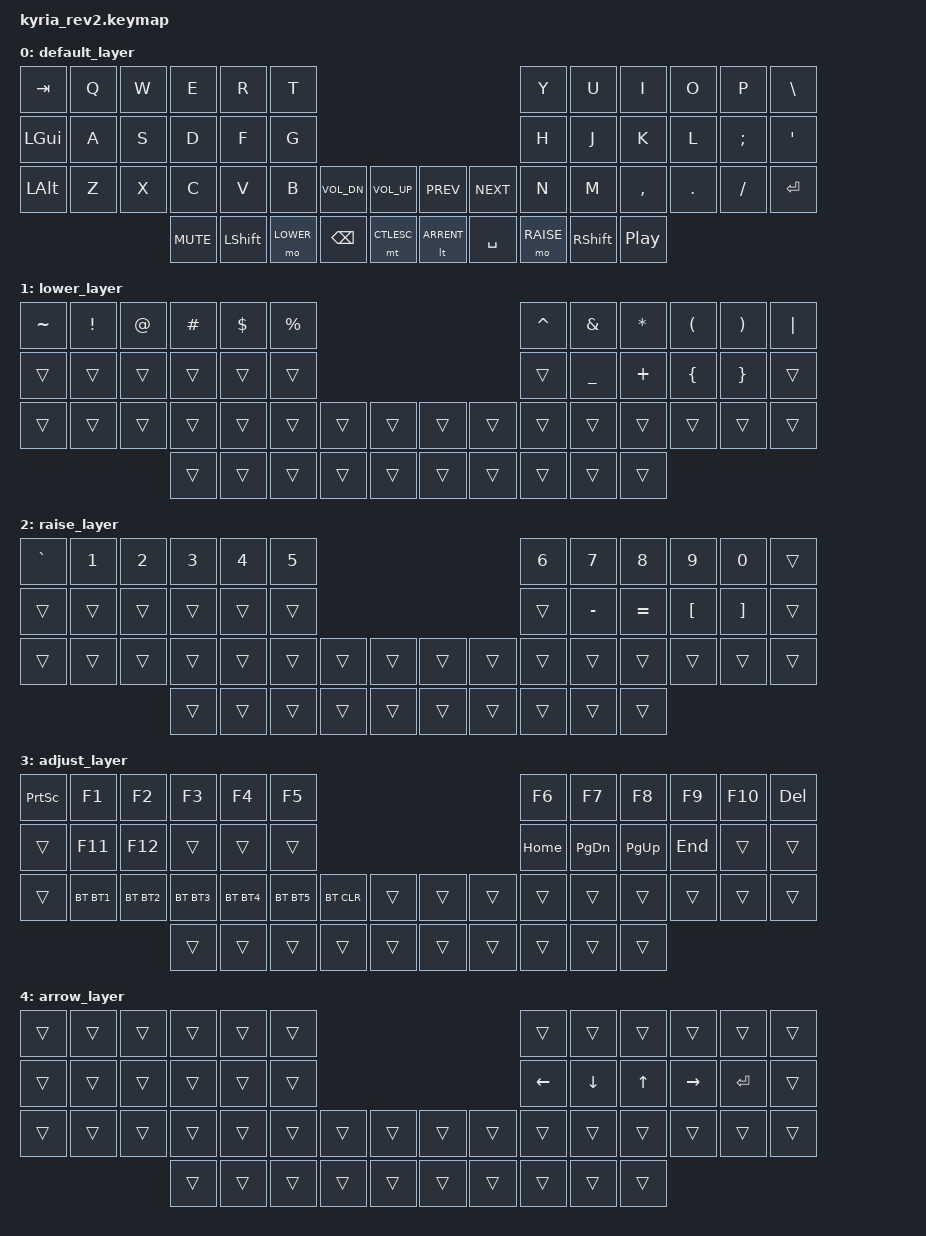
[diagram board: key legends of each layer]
/*
 * Copyright (c) 2020 Sam Balana
 *
 * SPDX-License-Identifier: MIT
 */

#include <behaviors.dtsi>
#include <dt-bindings/zmk/bt.h>
#include <dt-bindings/zmk/keys.h>

#define LOWER 1
#define RAISE 2
#define ADJUST 3
#define ARROW 4

#define VOL_DN C_VOL_DN
#define VOL_UP C_VOL_UP

// Shorthand keys
#define CTLESC LCTRL ESC
#define ARRENT ARROW RET
#define BT1    BT_SEL 0
#define BT2    BT_SEL 1
#define BT3    BT_SEL 2
#define BT4    BT_SEL 3
#define BT5    BT_SEL 4

/ {
	conditional_layers {
        compatible = "zmk,conditional-layers";
        tri_layer {
            if-layers = <LOWER RAISE>;
            then-layer = <ADJUST>;
        };
	};

	keymap {
		compatible = "zmk,keymap";

		default_layer {
			bindings = <
/*
 * Default: QWERTY
 *
 * ,-----------------------------------------.                              ,-----------------------------------------.
 * |  Tab |   Q  |   W  |   E  |   R  |   T  |                              |   Y  |   U  |   I  |   O  |   P  | \ |  |
 * |------+------+------+------+------+------|                              |------+------+------+------+------+------|
 * |  GUI |   A  |   S  |   D  |   F  |   G  |                              |   H  |   J  |   K  |   L  | ;  : | ' "  |
 * |------+------+------+------+------+------+-------------.  ,-------------+------+------+------+------+------+------|
 * | LAlt |   Z  |   X  |   C  |   V  |   B  | VolDn| VolUp|  | Prev | Next |   N  |   M  | ,  < | . >  | /  ? |Enter |
 * `--------------------+------+------+------+------+------|  |------+------+------+------+------+--------------------'
 *                      | Mute | LShft| Lower| Bksp |Ctl/Es|  |Arr/En|Space |Raise |RShft | Play |
 *                      `----------------------------------'  `----------------------------------'
 */
	&kp TAB    &kp Q      &kp W      &kp E      &kp R      &kp T                                                  &kp Y      &kp U      &kp I      &kp O      &kp P      &kp BSLH
	&kp LGUI   &kp A      &kp S      &kp D      &kp F      &kp G                                                  &kp H      &kp J      &kp K      &kp L      &kp SEMI   &kp SQT
	&kp LALT   &kp Z      &kp X      &kp C      &kp V      &kp B      &kp VOL_DN &kp VOL_UP &kp C_PREV &kp C_NEXT &kp N      &kp M      &kp COMMA  &kp DOT    &kp FSLH &kp ENTER
	                                 &kp C_MUTE &kp LSHFT  &mo LOWER  &kp BSPC   &mt CTLESC &lt ARRENT &kp SPACE  &mo RAISE  &kp RSHFT  &kp C_PP
			>;
		};

		lower_layer {
			bindings = <
/*
 * Lower: Symbols
 *
 * ,-----------------------------------------.                              ,-----------------------------------------.
 * |   ~  |   !  |   @  |   #  |   $  |   %  |                              |   ^  |   &  |   *  |   (  |   )  |  |   |
 * |------+------+------+------+------+------|                              |------+------+------+------+------+------|
 * |      |      |      |      |      |      |                              |      |   _  |   +  |   {  |   }  |      |
 * |------+------+------+------+------+------+-------------.  ,-------------+------+------+------+------+------+------|
 * |      |      |      |      |      |      |      |      |  |      |      |      |      |      |      |      |      |
 * `--------------------+------+------+------+------+------|  |------+------+------+------+------+--------------------'
 *                      |      |      |      |      |      |  |      |      |      |      |      |
 *                      `----------------------------------'  `----------------------------------'
 */
	&kp TILDE  &kp EXCL   &kp AT     &kp HASH   &kp DLLR   &kp PRCNT                                              &kp CARET  &kp AMPS   &kp STAR   &kp LPAR   &kp RPAR   &kp PIPE
	&trans     &trans     &trans     &trans     &trans     &trans                                                 &trans     &kp UNDER  &kp PLUS   &kp LBRC   &kp RBRC   &trans
	&trans     &trans     &trans     &trans     &trans     &trans     &trans     &trans     &trans     &trans     &trans     &trans     &trans     &trans     &trans     &trans
	                                 &trans     &trans     &trans     &trans     &trans     &trans     &trans     &trans     &trans     &trans
			>;
		};

		raise_layer {
			bindings = <
/*
 * Raise: Numbers
 *
 * ,-----------------------------------------.                              ,-----------------------------------------.
 * |   `  |   1  |  2   |  3   |  4   |  5   |                              |   6  |   7  |   8  |   9  |   0  |      |
 * |------+------+------+------+------+------|                              |------+------+------+------+------+------|
 * |      |      |      |      |      |      |                              |      |   -  |   =  |   [  |   ]  |      |
 * |------+------+------+------+------+------+-------------.  ,-------------+------+------+------+------+------+------|
 * |      |      |      |      |      |      |      |      |  |      |      |      |      |      |      |      |      |
 * `--------------------+------+------+------+------+------|  |------+------+------+------+------+--------------------'
 *                      |      |      |      |      |      |  |      |      |      |      |      |
 *                      `----------------------------------'  `----------------------------------'
 */
	&kp GRAVE  &kp N1     &kp N2     &kp N3     &kp N4     &kp N5                                                 &kp N6     &kp N7     &kp N8     &kp N9     &kp N0     &trans
	&trans     &trans     &trans     &trans     &trans     &trans                                                 &trans     &kp MINUS  &kp EQUAL  &kp LBKT   &kp RBKT   &trans
	&trans     &trans     &trans     &trans     &trans     &trans     &trans     &trans     &trans     &trans     &trans     &trans     &trans     &trans     &trans     &trans
	                                 &trans     &trans     &trans     &trans     &trans     &trans     &trans     &trans     &trans     &trans
			>;
		};

		adjust_layer {
			bindings = <
/*
 * Adjust: Function keys
 *
 * ,-----------------------------------------.                              ,-----------------------------------------.
 * | Print|  F1  |  F2  |  F3  |  F4  |  F5  |                              |  F6  |  F7  |  F8  |  F9  |  F10 |  Del |
 * |------+------+------+------+------+------|                              |------+------+------+------+------+------|
 * |      |  F11 |  F12 |      |      |      |                              | Home | PgDn | PgUp | End  |      |      |
 * |------+------+------+------+------+------+-------------.  ,-------------+------+------+------+------+------+------|
 * |      |  BT1 |  BT2 |  BT3 |  BT4 |  BT5 | BTCLR|      |  |      |      |      |      |      |      |      |      |
 * `--------------------+------+------+------+------+------|  |------+------+------+------+------+--------------------'
 *                      |      |      |      |      |      |  |      |      |      |      |      |
 *                      `----------------------------------'  `----------------------------------'
 */
	&kp PSCRN  &kp F1     &kp F2     &kp F3     &kp F4     &kp F5                                                 &kp F6     &kp F7     &kp F8     &kp F9     &kp F10    &kp DEL
	&trans     &kp F11    &kp F12    &trans     &trans     &trans                                                 &kp HOME   &kp PG_DN  &kp PG_UP  &kp END    &trans     &trans
	&trans     &bt BT1    &bt BT2    &bt BT3    &bt BT4    &bt BT5    &bt BT_CLR &trans     &trans     &trans     &trans     &trans     &trans     &trans     &trans     &trans
	                                 &trans     &trans     &trans     &trans     &trans     &trans     &trans     &trans     &trans     &trans
			>;
		};

		arrow_layer {
			bindings = <
/*
 * Arrow
 *
 * ,-----------------------------------------.                              ,-----------------------------------------.
 * |      |      |      |      |      |      |                              |      |      |      |      |      |      |
 * |------+------+------+------+------+------|                              |------+------+------+------+------+------|
 * |      |      |      |      |      |      |                              | Left | Down |  Up  |Right |Enter |      |
 * |------+------+------+------+------+------+-------------.  ,-------------+------+------+------+------+------+------|
 * |      |      |      |      |      |      |      |      |  |      |      |      |      |      |      |      |      |
 * `--------------------+------+------+------+------+------|  |------+------+------+------+------+--------------------'
 *                      |      |      |      |      |      |  |      |      |      |      |      |
 *                      `----------------------------------'  `----------------------------------'
 */
	&trans     &trans     &trans     &trans     &trans     &trans                                                 &trans     &trans     &trans     &trans     &trans     &trans
	&trans     &trans     &trans     &trans     &trans     &trans                                                 &kp LEFT   &kp DOWN   &kp UP     &kp RIGHT  &kp ENTER  &trans
	&trans     &trans     &trans     &trans     &trans     &trans     &trans     &trans     &trans     &trans     &trans     &trans     &trans     &trans     &trans     &trans
	                                 &trans     &trans     &trans     &trans     &trans     &trans     &trans     &trans     &trans     &trans
			>;
		};

	};
};
